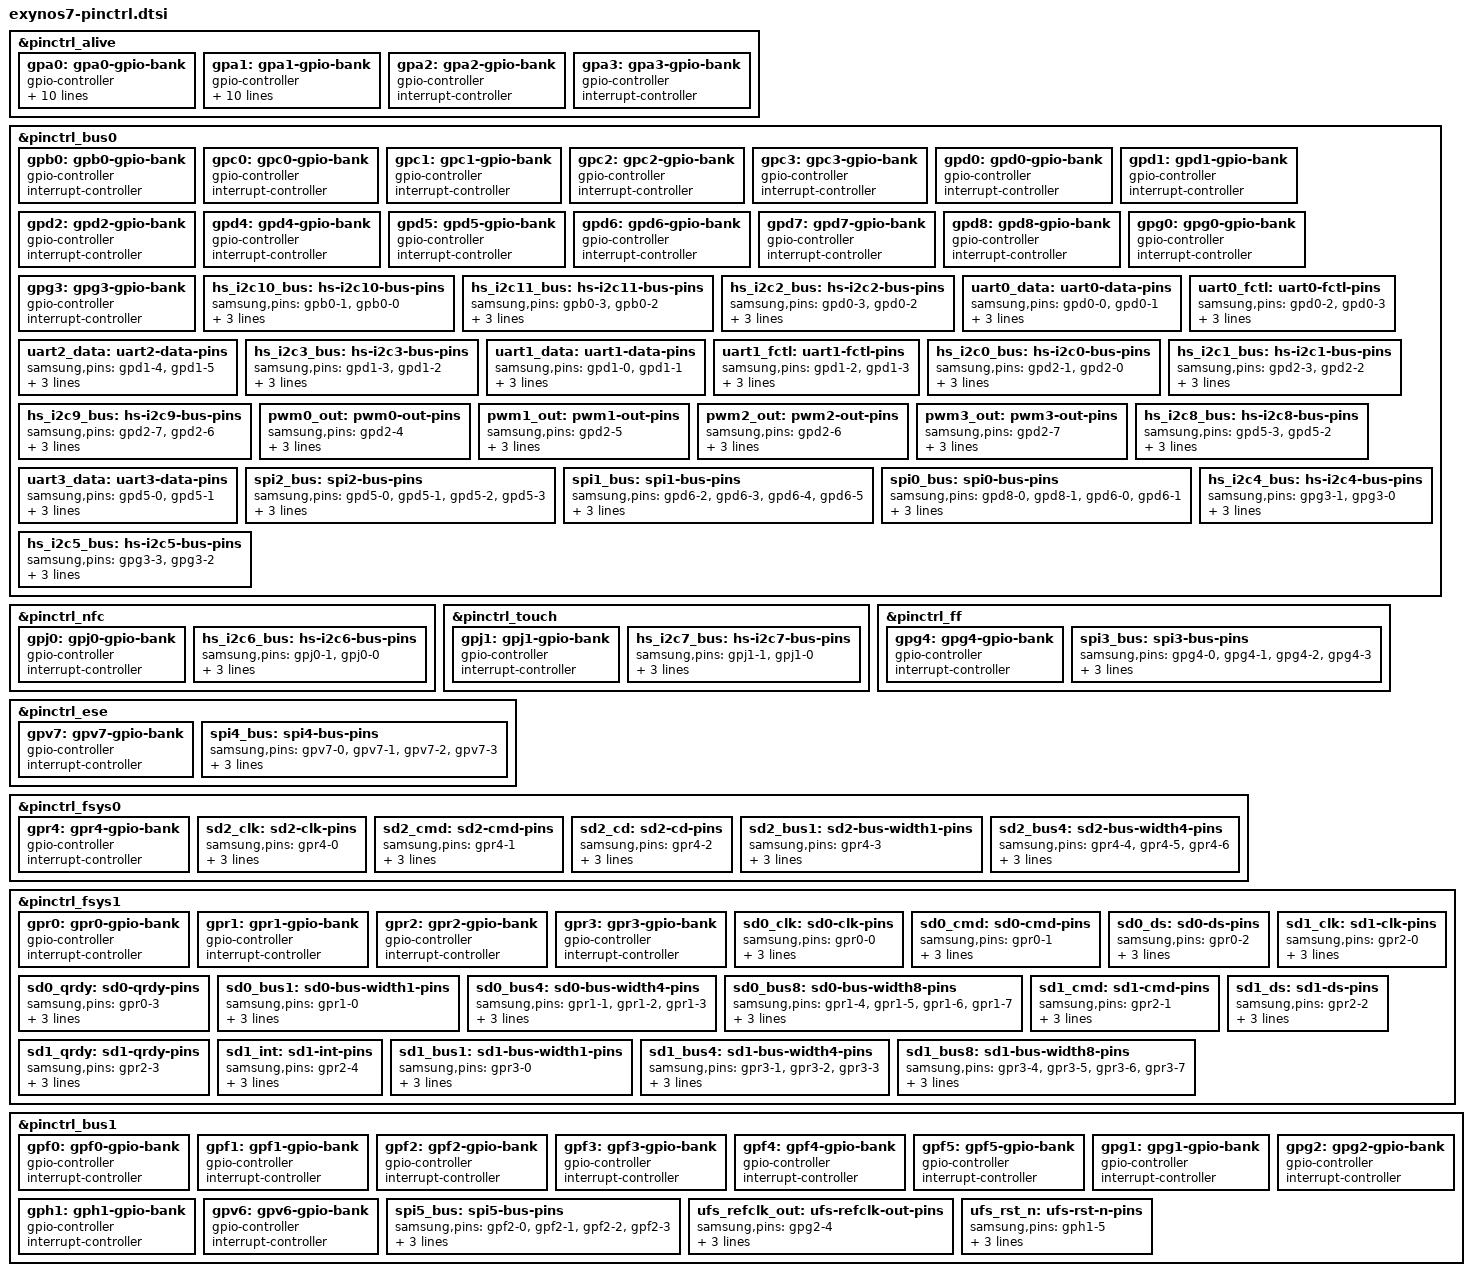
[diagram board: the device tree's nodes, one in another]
// SPDX-License-Identifier: GPL-2.0
/*
 * Samsung's Exynos7 SoC pin-mux and pin-config device tree source
 *
 * Copyright (c) 2014 Samsung Electronics Co., Ltd.
 *		http://www.samsung.com
 *
 * Samsung's Exynos7 SoC pin-mux and pin-config options are listed as
 * device tree nodes in this file.
 */

#include "exynos-pinctrl.h"

&pinctrl_alive {
	gpa0: gpa0-gpio-bank {
		gpio-controller;
		#gpio-cells = <2>;

		interrupt-controller;
		interrupt-parent = <&gic>;
		#interrupt-cells = <2>;
		interrupts = <GIC_SPI 0 IRQ_TYPE_LEVEL_HIGH>,
			     <GIC_SPI 1 IRQ_TYPE_LEVEL_HIGH>,
			     <GIC_SPI 2 IRQ_TYPE_LEVEL_HIGH>,
			     <GIC_SPI 3 IRQ_TYPE_LEVEL_HIGH>,
			     <GIC_SPI 4 IRQ_TYPE_LEVEL_HIGH>,
			     <GIC_SPI 5 IRQ_TYPE_LEVEL_HIGH>,
			     <GIC_SPI 6 IRQ_TYPE_LEVEL_HIGH>,
			     <GIC_SPI 7 IRQ_TYPE_LEVEL_HIGH>;
	};

	gpa1: gpa1-gpio-bank {
		gpio-controller;
		#gpio-cells = <2>;

		interrupt-controller;
		interrupt-parent = <&gic>;
		#interrupt-cells = <2>;
		interrupts = <GIC_SPI 8 IRQ_TYPE_LEVEL_HIGH>,
			     <GIC_SPI 9 IRQ_TYPE_LEVEL_HIGH>,
			     <GIC_SPI 10 IRQ_TYPE_LEVEL_HIGH>,
			     <GIC_SPI 11 IRQ_TYPE_LEVEL_HIGH>,
			     <GIC_SPI 12 IRQ_TYPE_LEVEL_HIGH>,
			     <GIC_SPI 13 IRQ_TYPE_LEVEL_HIGH>,
			     <GIC_SPI 14 IRQ_TYPE_LEVEL_HIGH>,
			     <GIC_SPI 15 IRQ_TYPE_LEVEL_HIGH>;
	};

	gpa2: gpa2-gpio-bank {
		gpio-controller;
		#gpio-cells = <2>;

		interrupt-controller;
		#interrupt-cells = <2>;
	};

	gpa3: gpa3-gpio-bank {
		gpio-controller;
		#gpio-cells = <2>;

		interrupt-controller;
		#interrupt-cells = <2>;
	};
};

&pinctrl_bus0 {
	gpb0: gpb0-gpio-bank {
		gpio-controller;
		#gpio-cells = <2>;

		interrupt-controller;
		#interrupt-cells = <2>;
	};

	gpc0: gpc0-gpio-bank {
		gpio-controller;
		#gpio-cells = <2>;

		interrupt-controller;
		#interrupt-cells = <2>;
	};

	gpc1: gpc1-gpio-bank {
		gpio-controller;
		#gpio-cells = <2>;

		interrupt-controller;
		#interrupt-cells = <2>;
	};

	gpc2: gpc2-gpio-bank {
		gpio-controller;
		#gpio-cells = <2>;

		interrupt-controller;
		#interrupt-cells = <2>;
	};

	gpc3: gpc3-gpio-bank {
		gpio-controller;
		#gpio-cells = <2>;

		interrupt-controller;
		#interrupt-cells = <2>;
	};

	gpd0: gpd0-gpio-bank {
		gpio-controller;
		#gpio-cells = <2>;

		interrupt-controller;
		#interrupt-cells = <2>;
	};

	gpd1: gpd1-gpio-bank {
		gpio-controller;
		#gpio-cells = <2>;

		interrupt-controller;
		#interrupt-cells = <2>;
	};

	gpd2: gpd2-gpio-bank {
		gpio-controller;
		#gpio-cells = <2>;

		interrupt-controller;
		#interrupt-cells = <2>;
	};

	gpd4: gpd4-gpio-bank {
		gpio-controller;
		#gpio-cells = <2>;

		interrupt-controller;
		#interrupt-cells = <2>;
	};

	gpd5: gpd5-gpio-bank {
		gpio-controller;
		#gpio-cells = <2>;

		interrupt-controller;
		#interrupt-cells = <2>;
	};

	gpd6: gpd6-gpio-bank {
		gpio-controller;
		#gpio-cells = <2>;

		interrupt-controller;
		#interrupt-cells = <2>;
	};

	gpd7: gpd7-gpio-bank {
		gpio-controller;
		#gpio-cells = <2>;

		interrupt-controller;
		#interrupt-cells = <2>;
	};

	gpd8: gpd8-gpio-bank {
		gpio-controller;
		#gpio-cells = <2>;

		interrupt-controller;
		#interrupt-cells = <2>;
	};

	gpg0: gpg0-gpio-bank {
		gpio-controller;
		#gpio-cells = <2>;

		interrupt-controller;
		#interrupt-cells = <2>;
	};

	gpg3: gpg3-gpio-bank {
		gpio-controller;
		#gpio-cells = <2>;

		interrupt-controller;
		#interrupt-cells = <2>;
	};

	hs_i2c10_bus: hs-i2c10-bus-pins {
		samsung,pins = "gpb0-1", "gpb0-0";
		samsung,pin-function = <EXYNOS_PIN_FUNC_2>;
		samsung,pin-pud = <EXYNOS_PIN_PULL_UP>;
		samsung,pin-drv = <EXYNOS7_PIN_DRV_LV1>;
	};

	hs_i2c11_bus: hs-i2c11-bus-pins {
		samsung,pins = "gpb0-3", "gpb0-2";
		samsung,pin-function = <EXYNOS_PIN_FUNC_2>;
		samsung,pin-pud = <EXYNOS_PIN_PULL_UP>;
		samsung,pin-drv = <EXYNOS7_PIN_DRV_LV1>;
	};

	hs_i2c2_bus: hs-i2c2-bus-pins {
		samsung,pins = "gpd0-3", "gpd0-2";
		samsung,pin-function = <EXYNOS_PIN_FUNC_3>;
		samsung,pin-pud = <EXYNOS_PIN_PULL_UP>;
		samsung,pin-drv = <EXYNOS7_PIN_DRV_LV1>;
	};

	uart0_data: uart0-data-pins {
		samsung,pins = "gpd0-0", "gpd0-1";
		samsung,pin-function = <EXYNOS_PIN_FUNC_2>;
		samsung,pin-pud = <EXYNOS_PIN_PULL_NONE>;
		samsung,pin-drv = <EXYNOS7_PIN_DRV_LV1>;
	};

	uart0_fctl: uart0-fctl-pins {
		samsung,pins = "gpd0-2", "gpd0-3";
		samsung,pin-function = <EXYNOS_PIN_FUNC_2>;
		samsung,pin-pud = <EXYNOS_PIN_PULL_NONE>;
		samsung,pin-drv = <EXYNOS7_PIN_DRV_LV1>;
	};

	uart2_data: uart2-data-pins {
		samsung,pins = "gpd1-4", "gpd1-5";
		samsung,pin-function = <EXYNOS_PIN_FUNC_2>;
		samsung,pin-pud = <EXYNOS_PIN_PULL_NONE>;
		samsung,pin-drv = <EXYNOS7_PIN_DRV_LV1>;
	};

	hs_i2c3_bus: hs-i2c3-bus-pins {
		samsung,pins = "gpd1-3", "gpd1-2";
		samsung,pin-function = <EXYNOS_PIN_FUNC_3>;
		samsung,pin-pud = <EXYNOS_PIN_PULL_UP>;
		samsung,pin-drv = <EXYNOS7_PIN_DRV_LV1>;
	};

	uart1_data: uart1-data-pins {
		samsung,pins = "gpd1-0", "gpd1-1";
		samsung,pin-function = <EXYNOS_PIN_FUNC_2>;
		samsung,pin-pud = <EXYNOS_PIN_PULL_NONE>;
		samsung,pin-drv = <EXYNOS7_PIN_DRV_LV1>;
	};

	uart1_fctl: uart1-fctl-pins {
		samsung,pins = "gpd1-2", "gpd1-3";
		samsung,pin-function = <EXYNOS_PIN_FUNC_2>;
		samsung,pin-pud = <EXYNOS_PIN_PULL_NONE>;
		samsung,pin-drv = <EXYNOS7_PIN_DRV_LV1>;
	};

	hs_i2c0_bus: hs-i2c0-bus-pins {
		samsung,pins = "gpd2-1", "gpd2-0";
		samsung,pin-function = <EXYNOS_PIN_FUNC_2>;
		samsung,pin-pud = <EXYNOS_PIN_PULL_UP>;
		samsung,pin-drv = <EXYNOS7_PIN_DRV_LV1>;
	};

	hs_i2c1_bus: hs-i2c1-bus-pins {
		samsung,pins = "gpd2-3", "gpd2-2";
		samsung,pin-function = <EXYNOS_PIN_FUNC_2>;
		samsung,pin-pud = <EXYNOS_PIN_PULL_UP>;
		samsung,pin-drv = <EXYNOS7_PIN_DRV_LV1>;
	};

	hs_i2c9_bus: hs-i2c9-bus-pins {
		samsung,pins = "gpd2-7", "gpd2-6";
		samsung,pin-function = <EXYNOS_PIN_FUNC_3>;
		samsung,pin-pud = <EXYNOS_PIN_PULL_UP>;
		samsung,pin-drv = <EXYNOS7_PIN_DRV_LV1>;
	};

	pwm0_out: pwm0-out-pins {
		samsung,pins = "gpd2-4";
		samsung,pin-function = <EXYNOS_PIN_FUNC_2>;
		samsung,pin-pud = <EXYNOS_PIN_PULL_NONE>;
		samsung,pin-drv = <EXYNOS7_PIN_DRV_LV1>;
	};

	pwm1_out: pwm1-out-pins {
		samsung,pins = "gpd2-5";
		samsung,pin-function = <EXYNOS_PIN_FUNC_2>;
		samsung,pin-pud = <EXYNOS_PIN_PULL_NONE>;
		samsung,pin-drv = <EXYNOS7_PIN_DRV_LV1>;
	};

	pwm2_out: pwm2-out-pins {
		samsung,pins = "gpd2-6";
		samsung,pin-function = <EXYNOS_PIN_FUNC_2>;
		samsung,pin-pud = <EXYNOS_PIN_PULL_NONE>;
		samsung,pin-drv = <EXYNOS7_PIN_DRV_LV1>;
	};

	pwm3_out: pwm3-out-pins {
		samsung,pins = "gpd2-7";
		samsung,pin-function = <EXYNOS_PIN_FUNC_2>;
		samsung,pin-pud = <EXYNOS_PIN_PULL_NONE>;
		samsung,pin-drv = <EXYNOS7_PIN_DRV_LV1>;
	};

	hs_i2c8_bus: hs-i2c8-bus-pins {
		samsung,pins = "gpd5-3", "gpd5-2";
		samsung,pin-function = <EXYNOS_PIN_FUNC_3>;
		samsung,pin-pud = <EXYNOS_PIN_PULL_UP>;
		samsung,pin-drv = <EXYNOS7_PIN_DRV_LV1>;
	};

	uart3_data: uart3-data-pins {
		samsung,pins = "gpd5-0", "gpd5-1";
		samsung,pin-function = <EXYNOS_PIN_FUNC_3>;
		samsung,pin-pud = <EXYNOS_PIN_PULL_NONE>;
		samsung,pin-drv = <EXYNOS7_PIN_DRV_LV1>;
	};

	spi2_bus: spi2-bus-pins {
		samsung,pins = "gpd5-0", "gpd5-1", "gpd5-2", "gpd5-3";
		samsung,pin-function = <EXYNOS_PIN_FUNC_2>;
		samsung,pin-pud = <EXYNOS_PIN_PULL_UP>;
		samsung,pin-drv = <EXYNOS7_PIN_DRV_LV1>;
	};

	spi1_bus: spi1-bus-pins {
		samsung,pins = "gpd6-2", "gpd6-3", "gpd6-4", "gpd6-5";
		samsung,pin-function = <EXYNOS_PIN_FUNC_2>;
		samsung,pin-pud = <EXYNOS_PIN_PULL_UP>;
		samsung,pin-drv = <EXYNOS7_PIN_DRV_LV1>;
	};

	spi0_bus: spi0-bus-pins {
		samsung,pins = "gpd8-0", "gpd8-1", "gpd6-0", "gpd6-1";
		samsung,pin-function = <EXYNOS_PIN_FUNC_2>;
		samsung,pin-pud = <EXYNOS_PIN_PULL_UP>;
		samsung,pin-drv = <EXYNOS7_PIN_DRV_LV1>;
	};

	hs_i2c4_bus: hs-i2c4-bus-pins {
		samsung,pins = "gpg3-1", "gpg3-0";
		samsung,pin-function = <EXYNOS_PIN_FUNC_2>;
		samsung,pin-pud = <EXYNOS_PIN_PULL_UP>;
		samsung,pin-drv = <EXYNOS7_PIN_DRV_LV1>;
	};

	hs_i2c5_bus: hs-i2c5-bus-pins {
		samsung,pins = "gpg3-3", "gpg3-2";
		samsung,pin-function = <EXYNOS_PIN_FUNC_2>;
		samsung,pin-pud = <EXYNOS_PIN_PULL_UP>;
		samsung,pin-drv = <EXYNOS7_PIN_DRV_LV1>;
	};
};

&pinctrl_nfc {
	gpj0: gpj0-gpio-bank {
		gpio-controller;
		#gpio-cells = <2>;

		interrupt-controller;
		#interrupt-cells = <2>;
	};

	hs_i2c6_bus: hs-i2c6-bus-pins {
		samsung,pins = "gpj0-1", "gpj0-0";
		samsung,pin-function = <EXYNOS_PIN_FUNC_2>;
		samsung,pin-pud = <EXYNOS_PIN_PULL_UP>;
		samsung,pin-drv = <EXYNOS7_PIN_DRV_LV1>;
	};
};

&pinctrl_touch {
	gpj1: gpj1-gpio-bank {
		gpio-controller;
		#gpio-cells = <2>;

		interrupt-controller;
		#interrupt-cells = <2>;
	};

	hs_i2c7_bus: hs-i2c7-bus-pins {
		samsung,pins = "gpj1-1", "gpj1-0";
		samsung,pin-function = <EXYNOS_PIN_FUNC_2>;
		samsung,pin-pud = <EXYNOS_PIN_PULL_UP>;
		samsung,pin-drv = <EXYNOS7_PIN_DRV_LV1>;
	};
};

&pinctrl_ff {
	gpg4: gpg4-gpio-bank {
		gpio-controller;
		#gpio-cells = <2>;

		interrupt-controller;
		#interrupt-cells = <2>;
	};

	spi3_bus: spi3-bus-pins {
		samsung,pins = "gpg4-0", "gpg4-1", "gpg4-2", "gpg4-3";
		samsung,pin-function = <EXYNOS_PIN_FUNC_2>;
		samsung,pin-pud = <EXYNOS_PIN_PULL_UP>;
		samsung,pin-drv = <EXYNOS7_PIN_DRV_LV1>;
	};
};

&pinctrl_ese {
	gpv7: gpv7-gpio-bank {
		gpio-controller;
		#gpio-cells = <2>;

		interrupt-controller;
		#interrupt-cells = <2>;
	};

	spi4_bus: spi4-bus-pins {
		samsung,pins = "gpv7-0", "gpv7-1", "gpv7-2", "gpv7-3";
		samsung,pin-function = <EXYNOS_PIN_FUNC_2>;
		samsung,pin-pud = <EXYNOS_PIN_PULL_UP>;
		samsung,pin-drv = <EXYNOS7_PIN_DRV_LV1>;
	};
};

&pinctrl_fsys0 {
	gpr4: gpr4-gpio-bank {
		gpio-controller;
		#gpio-cells = <2>;

		interrupt-controller;
		#interrupt-cells = <2>;
	};

	sd2_clk: sd2-clk-pins {
		samsung,pins = "gpr4-0";
		samsung,pin-function = <EXYNOS_PIN_FUNC_2>;
		samsung,pin-pud = <EXYNOS_PIN_PULL_NONE>;
		samsung,pin-drv = <EXYNOS7_PIN_DRV_LV4>;
	};

	sd2_cmd: sd2-cmd-pins {
		samsung,pins = "gpr4-1";
		samsung,pin-function = <EXYNOS_PIN_FUNC_2>;
		samsung,pin-pud = <EXYNOS_PIN_PULL_NONE>;
		samsung,pin-drv = <EXYNOS7_PIN_DRV_LV4>;
	};

	sd2_cd: sd2-cd-pins {
		samsung,pins = "gpr4-2";
		samsung,pin-function = <EXYNOS_PIN_FUNC_2>;
		samsung,pin-pud = <EXYNOS_PIN_PULL_UP>;
		samsung,pin-drv = <EXYNOS7_PIN_DRV_LV4>;
	};

	sd2_bus1: sd2-bus-width1-pins {
		samsung,pins = "gpr4-3";
		samsung,pin-function = <EXYNOS_PIN_FUNC_2>;
		samsung,pin-pud = <EXYNOS_PIN_PULL_UP>;
		samsung,pin-drv = <EXYNOS7_PIN_DRV_LV4>;
	};

	sd2_bus4: sd2-bus-width4-pins {
		samsung,pins = "gpr4-4", "gpr4-5", "gpr4-6";
		samsung,pin-function = <EXYNOS_PIN_FUNC_2>;
		samsung,pin-pud = <EXYNOS_PIN_PULL_UP>;
		samsung,pin-drv = <EXYNOS7_PIN_DRV_LV4>;
	};
};

&pinctrl_fsys1 {
	gpr0: gpr0-gpio-bank {
		gpio-controller;
		#gpio-cells = <2>;

		interrupt-controller;
		#interrupt-cells = <2>;
	};

	gpr1: gpr1-gpio-bank {
		gpio-controller;
		#gpio-cells = <2>;

		interrupt-controller;
		#interrupt-cells = <2>;
	};

	gpr2: gpr2-gpio-bank {
		gpio-controller;
		#gpio-cells = <2>;

		interrupt-controller;
		#interrupt-cells = <2>;
	};

	gpr3: gpr3-gpio-bank {
		gpio-controller;
		#gpio-cells = <2>;

		interrupt-controller;
		#interrupt-cells = <2>;
	};

	sd0_clk: sd0-clk-pins {
		samsung,pins = "gpr0-0";
		samsung,pin-function = <EXYNOS_PIN_FUNC_2>;
		samsung,pin-pud = <EXYNOS_PIN_PULL_NONE>;
		samsung,pin-drv = <EXYNOS7_FSYS1_PIN_DRV_LV2>;
	};

	sd0_cmd: sd0-cmd-pins {
		samsung,pins = "gpr0-1";
		samsung,pin-function = <EXYNOS_PIN_FUNC_2>;
		samsung,pin-pud = <EXYNOS_PIN_PULL_UP>;
		samsung,pin-drv = <EXYNOS7_FSYS1_PIN_DRV_LV2>;
	};

	sd0_ds: sd0-ds-pins {
		samsung,pins = "gpr0-2";
		samsung,pin-function = <EXYNOS_PIN_FUNC_2>;
		samsung,pin-pud = <EXYNOS_PIN_PULL_DOWN>;
		samsung,pin-drv = <EXYNOS7_FSYS1_PIN_DRV_LV2>;
	};

	sd0_qrdy: sd0-qrdy-pins {
		samsung,pins = "gpr0-3";
		samsung,pin-function = <EXYNOS_PIN_FUNC_2>;
		samsung,pin-pud = <EXYNOS_PIN_PULL_DOWN>;
		samsung,pin-drv = <EXYNOS7_FSYS1_PIN_DRV_LV2>;
	};

	sd0_bus1: sd0-bus-width1-pins {
		samsung,pins = "gpr1-0";
		samsung,pin-function = <EXYNOS_PIN_FUNC_2>;
		samsung,pin-pud = <EXYNOS_PIN_PULL_UP>;
		samsung,pin-drv = <EXYNOS7_FSYS1_PIN_DRV_LV2>;
	};

	sd0_bus4: sd0-bus-width4-pins {
		samsung,pins = "gpr1-1", "gpr1-2", "gpr1-3";
		samsung,pin-function = <EXYNOS_PIN_FUNC_2>;
		samsung,pin-pud = <EXYNOS_PIN_PULL_UP>;
		samsung,pin-drv = <EXYNOS7_FSYS1_PIN_DRV_LV2>;
	};

	sd0_bus8: sd0-bus-width8-pins {
		samsung,pins = "gpr1-4", "gpr1-5", "gpr1-6", "gpr1-7";
		samsung,pin-function = <EXYNOS_PIN_FUNC_2>;
		samsung,pin-pud = <EXYNOS_PIN_PULL_UP>;
		samsung,pin-drv = <EXYNOS7_FSYS1_PIN_DRV_LV2>;
	};

	sd1_clk: sd1-clk-pins {
		samsung,pins = "gpr2-0";
		samsung,pin-function = <EXYNOS_PIN_FUNC_2>;
		samsung,pin-pud = <EXYNOS_PIN_PULL_NONE>;
		samsung,pin-drv = <EXYNOS7_FSYS1_PIN_DRV_LV3>;
	};

	sd1_cmd: sd1-cmd-pins {
		samsung,pins = "gpr2-1";
		samsung,pin-function = <EXYNOS_PIN_FUNC_2>;
		samsung,pin-pud = <EXYNOS_PIN_PULL_NONE>;
		samsung,pin-drv = <EXYNOS7_FSYS1_PIN_DRV_LV3>;
	};

	sd1_ds: sd1-ds-pins {
		samsung,pins = "gpr2-2";
		samsung,pin-function = <EXYNOS_PIN_FUNC_2>;
		samsung,pin-pud = <EXYNOS_PIN_PULL_DOWN>;
		samsung,pin-drv = <EXYNOS7_FSYS1_PIN_DRV_LV4>;
	};

	sd1_qrdy: sd1-qrdy-pins {
		samsung,pins = "gpr2-3";
		samsung,pin-function = <EXYNOS_PIN_FUNC_2>;
		samsung,pin-pud = <EXYNOS_PIN_PULL_DOWN>;
		samsung,pin-drv = <EXYNOS7_FSYS1_PIN_DRV_LV4>;
	};

	sd1_int: sd1-int-pins {
		samsung,pins = "gpr2-4";
		samsung,pin-function = <EXYNOS_PIN_FUNC_2>;
		samsung,pin-pud = <EXYNOS_PIN_PULL_DOWN>;
		samsung,pin-drv = <EXYNOS7_FSYS1_PIN_DRV_LV4>;
	};

	sd1_bus1: sd1-bus-width1-pins {
		samsung,pins = "gpr3-0";
		samsung,pin-function = <EXYNOS_PIN_FUNC_2>;
		samsung,pin-pud = <EXYNOS_PIN_PULL_UP>;
		samsung,pin-drv = <EXYNOS7_FSYS1_PIN_DRV_LV3>;
	};

	sd1_bus4: sd1-bus-width4-pins {
		samsung,pins = "gpr3-1", "gpr3-2", "gpr3-3";
		samsung,pin-function = <EXYNOS_PIN_FUNC_2>;
		samsung,pin-pud = <EXYNOS_PIN_PULL_UP>;
		samsung,pin-drv = <EXYNOS7_FSYS1_PIN_DRV_LV3>;
	};

	sd1_bus8: sd1-bus-width8-pins {
		samsung,pins = "gpr3-4", "gpr3-5", "gpr3-6", "gpr3-7";
		samsung,pin-function = <EXYNOS_PIN_FUNC_2>;
		samsung,pin-pud = <EXYNOS_PIN_PULL_UP>;
		samsung,pin-drv = <EXYNOS7_FSYS1_PIN_DRV_LV3>;
	};
};

&pinctrl_bus1 {
	gpf0: gpf0-gpio-bank {
		gpio-controller;
		#gpio-cells = <2>;

		interrupt-controller;
		#interrupt-cells = <2>;
	};

	gpf1: gpf1-gpio-bank {
		gpio-controller;
		#gpio-cells = <2>;

		interrupt-controller;
		#interrupt-cells = <2>;
	};

	gpf2: gpf2-gpio-bank {
		gpio-controller;
		#gpio-cells = <2>;

		interrupt-controller;
		#interrupt-cells = <2>;
	};

	gpf3: gpf3-gpio-bank {
		gpio-controller;
		#gpio-cells = <2>;

		interrupt-controller;
		#interrupt-cells = <2>;
	};

	gpf4: gpf4-gpio-bank {
		gpio-controller;
		#gpio-cells = <2>;

		interrupt-controller;
		#interrupt-cells = <2>;
	};

	gpf5: gpf5-gpio-bank {
		gpio-controller;
		#gpio-cells = <2>;

		interrupt-controller;
		#interrupt-cells = <2>;
	};

	gpg1: gpg1-gpio-bank {
		gpio-controller;
		#gpio-cells = <2>;

		interrupt-controller;
		#interrupt-cells = <2>;
	};

	gpg2: gpg2-gpio-bank {
		gpio-controller;
		#gpio-cells = <2>;

		interrupt-controller;
		#interrupt-cells = <2>;
	};

	gph1: gph1-gpio-bank {
		gpio-controller;
		#gpio-cells = <2>;

		interrupt-controller;
		#interrupt-cells = <2>;
	};

	gpv6: gpv6-gpio-bank {
		gpio-controller;
		#gpio-cells = <2>;

		interrupt-controller;
		#interrupt-cells = <2>;
	};

	spi5_bus: spi5-bus-pins {
		samsung,pins = "gpf2-0", "gpf2-1", "gpf2-2", "gpf2-3";
		samsung,pin-function = <EXYNOS_PIN_FUNC_2>;
		samsung,pin-pud = <EXYNOS_PIN_PULL_UP>;
		samsung,pin-drv = <EXYNOS7_PIN_DRV_LV1>;
	};

	ufs_refclk_out: ufs-refclk-out-pins {
		samsung,pins = "gpg2-4";
		samsung,pin-function = <EXYNOS_PIN_FUNC_2>;
		samsung,pin-pud = <EXYNOS_PIN_PULL_NONE>;
		samsung,pin-drv = <EXYNOS7_PIN_DRV_LV2>;
	};

	ufs_rst_n: ufs-rst-n-pins {
		samsung,pins = "gph1-5";
		samsung,pin-function = <EXYNOS_PIN_FUNC_2>;
		samsung,pin-pud = <EXYNOS_PIN_PULL_UP>;
		samsung,pin-drv = <EXYNOS7_PIN_DRV_LV1>;
	};
};
